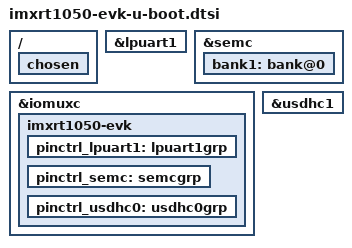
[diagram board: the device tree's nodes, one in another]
// SPDX-License-Identifier: (GPL-2.0+ OR BSD-3-Clause)
/*
 * Copyright (C) 2019
 * Author(s): Giulio Benetti <giulio.benetti@benettiengineering.com>
 */

/ {
	chosen {
		u-boot,dm-spl;
	};
};

&lpuart1 { /* console */
	u-boot,dm-spl;
};

&semc {
	bank1: bank@0 {
		u-boot,dm-spl;
	};
};

&iomuxc {
	u-boot,dm-spl;

	imxrt1050-evk {
		u-boot,dm-spl;
		pinctrl_lpuart1: lpuart1grp {
			u-boot,dm-spl;
		};

		pinctrl_semc: semcgrp {
			u-boot,dm-spl;
		};

		pinctrl_usdhc0: usdhc0grp {
			u-boot,dm-spl;
		};
	};
};

&usdhc1 {
	u-boot,dm-spl;
};
